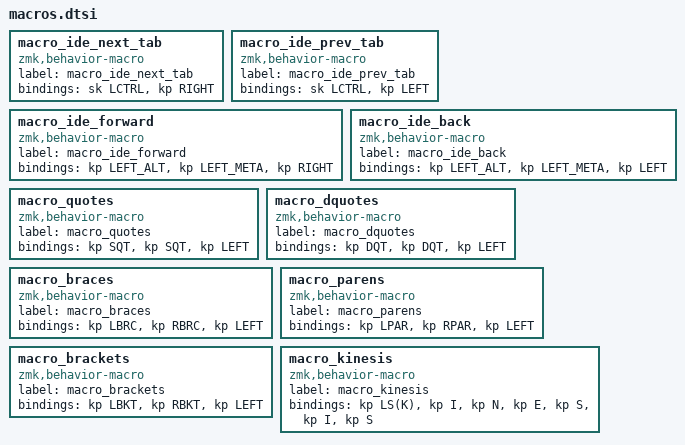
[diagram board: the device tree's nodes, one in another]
macro_ide_next_tab: macro_ide_next_tab{
compatible = "zmk,behavior-macro";
label = "macro_ide_next_tab";
#binding-cells = <0>;
bindings = <&sk LCTRL>, <&kp RIGHT>;
};
macro_ide_prev_tab: macro_ide_prev_tab{
compatible = "zmk,behavior-macro";
label = "macro_ide_prev_tab";
#binding-cells = <0>;
bindings = <&sk LCTRL>, <&kp LEFT>;
};
macro_ide_forward: macro_ide_forward{
compatible = "zmk,behavior-macro";
label = "macro_ide_forward";
#binding-cells = <0>;
bindings = <&kp LEFT_ALT>, <&kp LEFT_META>, <&kp RIGHT>;
};
macro_ide_back: macro_ide_back{
compatible = "zmk,behavior-macro";
label = "macro_ide_back";
#binding-cells = <0>;
bindings = <&kp LEFT_ALT>, <&kp LEFT_META>, <&kp LEFT>;
};
macro_quotes: macro_quotes{
compatible = "zmk,behavior-macro";
label = "macro_quotes";
#binding-cells = <0>;
bindings = <&kp SQT>, <&kp SQT>, <&kp LEFT>;
};
macro_dquotes: macro_dquotes{
compatible = "zmk,behavior-macro";
label = "macro_dquotes";
#binding-cells = <0>;
bindings = <&kp DQT>, <&kp DQT>, <&kp LEFT>;
};
macro_braces: macro_braces{
compatible = "zmk,behavior-macro";
label = "macro_braces";
#binding-cells = <0>;
bindings = <&kp LBRC>, <&kp RBRC>, <&kp LEFT>;
};
macro_parens: macro_parens{
compatible = "zmk,behavior-macro";
label = "macro_parens";
#binding-cells = <0>;
bindings = <&kp LPAR>, <&kp RPAR>, <&kp LEFT>;
};
macro_brackets: macro_brackets{
compatible = "zmk,behavior-macro";
label = "macro_brackets";
#binding-cells = <0>;
bindings = <&kp LBKT>, <&kp RBKT>, <&kp LEFT>;
};
macro_kinesis: macro_kinesis{
compatible = "zmk,behavior-macro";
label = "macro_kinesis";
#binding-cells = <0>;
bindings = <&kp LS(K)>, <&kp I>, <&kp N>, <&kp E>, <&kp S>, <&kp I>, <&kp S>;
};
